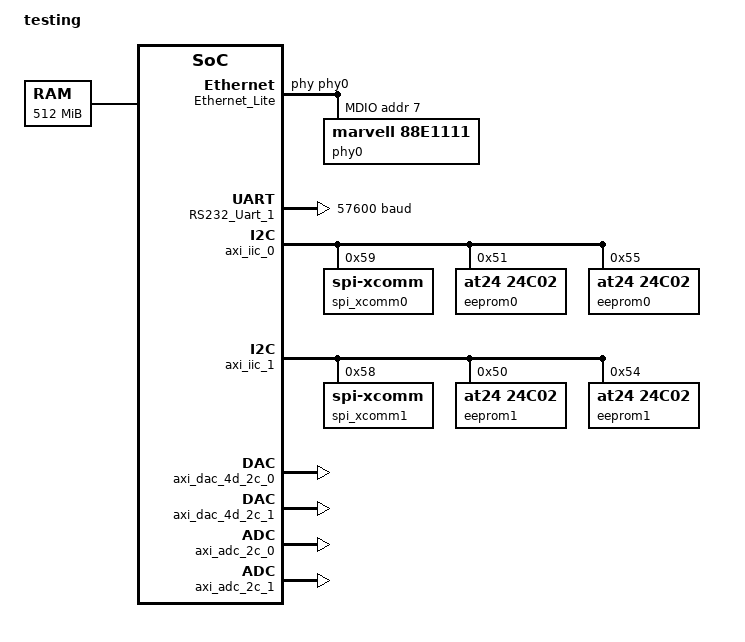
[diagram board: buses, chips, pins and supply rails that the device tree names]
/*
 * Device Tree Generator version: 1.3
 *
 * (C) Copyright 2007-2008 Xilinx, Inc.
 * (C) Copyright 2007-2009 Michal Simek
 *
 * Michal SIMEK <monstr@monstr.eu>
 *
 * This program is free software; you can redistribute it and/or
 * modify it under the terms of the GNU General Public License as
 * published by the Free Software Foundation; either version 2 of
 * the License, or (at your option) any later version.
 *
 * This program is distributed in the hope that it will be useful,
 * but WITHOUT ANY WARRANTY; without even the implied warranty of
 * MERCHANTABILITY or FITNESS FOR A PARTICULAR PURPOSE. See the
 * GNU General Public License for more details.
 *
 * You should have received a copy of the GNU General Public License
 * along with this program; if not, write to the Free Software
 * Foundation, Inc., 59 Temple Place, Suite 330, Boston,
 * MA 02111-1307 USA
 *
 * CAUTION: This file is automatically generated by libgen.
 * Version: Xilinx EDK 14.1 EDK_P.15xf
 *
 * XPS project directory: device-tree_bsp_0
 */

/dts-v1/;
/ {
	#address-cells = <1>;
	#size-cells = <1>;
	compatible = "xlnx,microblaze";
	model = "testing";
	DDR3_SDRAM: memory@c0000000 {
		device_type = "memory";
		reg = < 0xc0000000 0x20000000 >;
	} ;
	aliases {
		ethernet0 = &Ethernet_Lite;
		serial0 = &RS232_Uart_1;
	} ;
	chosen {
		bootargs = "console=ttyS0 root=/dev/ram";
	} ;
	cpus {
		#address-cells = <1>;
		#cpus = <0x1>;
		#size-cells = <0>;
		microblaze_0: cpu@0 {
			clock-frequency = <100000000>;
			compatible = "xlnx,microblaze-8.30.a";
			d-cache-baseaddr = <0xc0000000>;
			d-cache-highaddr = <0xdfffffff>;
			d-cache-line-size = <0x10>;
			d-cache-size = <0x4000>;
			device_type = "cpu";
			i-cache-baseaddr = <0xc0000000>;
			i-cache-highaddr = <0xdfffffff>;
			i-cache-line-size = <0x20>;
			i-cache-size = <0x4000>;
			model = "microblaze,8.30.a";
			reg = <0>;
			timebase-frequency = <100000000>;
			xlnx,addr-tag-bits = <0xf>;
			xlnx,allow-dcache-wr = <0x1>;
			xlnx,allow-icache-wr = <0x1>;
			xlnx,area-optimized = <0x0>;
			xlnx,avoid-primitives = <0x0>;
			xlnx,branch-target-cache-size = <0x0>;
			xlnx,cache-byte-size = <0x4000>;
			xlnx,d-axi = <0x1>;
			xlnx,d-lmb = <0x1>;
			xlnx,d-plb = <0x0>;
			xlnx,data-size = <0x20>;
			xlnx,dcache-addr-tag = <0xf>;
			xlnx,dcache-always-used = <0x1>;
			xlnx,dcache-byte-size = <0x4000>;
			xlnx,dcache-data-width = <0x0>;
			xlnx,dcache-force-tag-lutram = <0x0>;
			xlnx,dcache-interface = <0x0>;
			xlnx,dcache-line-len = <0x4>;
			xlnx,dcache-use-fsl = <0x0>;
			xlnx,dcache-use-writeback = <0x0>;
			xlnx,dcache-victims = <0x0>;
			xlnx,debug-enabled = <0x1>;
			xlnx,div-zero-exception = <0x1>;
			xlnx,dynamic-bus-sizing = <0x1>;
			xlnx,ecc-use-ce-exception = <0x0>;
			xlnx,edge-is-positive = <0x1>;
			xlnx,endianness = <0x1>;
			xlnx,family = "virtex6";
			xlnx,fault-tolerant = <0x0>;
			xlnx,fpu-exception = <0x0>;
			xlnx,freq = <0x5f5e100>;
			xlnx,fsl-data-size = <0x20>;
			xlnx,fsl-exception = <0x0>;
			xlnx,fsl-links = <0x0>;
			xlnx,i-axi = <0x0>;
			xlnx,i-lmb = <0x1>;
			xlnx,i-plb = <0x0>;
			xlnx,icache-always-used = <0x1>;
			xlnx,icache-data-width = <0x0>;
			xlnx,icache-force-tag-lutram = <0x0>;
			xlnx,icache-interface = <0x0>;
			xlnx,icache-line-len = <0x8>;
			xlnx,icache-streams = <0x1>;
			xlnx,icache-use-fsl = <0x0>;
			xlnx,icache-victims = <0x8>;
			xlnx,ill-opcode-exception = <0x1>;
			xlnx,instance = "microblaze_0";
			xlnx,interconnect = <0x2>;
			xlnx,interconnect-m-axi-dc-read-issuing = <0x2>;
			xlnx,interconnect-m-axi-dc-write-issuing = <0x20>;
			xlnx,interconnect-m-axi-dp-read-issuing = <0x1>;
			xlnx,interconnect-m-axi-dp-write-issuing = <0x1>;
			xlnx,interconnect-m-axi-ic-read-issuing = <0x8>;
			xlnx,interconnect-m-axi-ip-read-issuing = <0x1>;
			xlnx,interrupt-is-edge = <0x0>;
			xlnx,lockstep-slave = <0x0>;
			xlnx,mmu-dtlb-size = <0x4>;
			xlnx,mmu-itlb-size = <0x2>;
			xlnx,mmu-privileged-instr = <0x0>;
			xlnx,mmu-tlb-access = <0x3>;
			xlnx,mmu-zones = <0x2>;
			xlnx,number-of-pc-brk = <0x1>;
			xlnx,number-of-rd-addr-brk = <0x0>;
			xlnx,number-of-wr-addr-brk = <0x0>;
			xlnx,opcode-0x0-illegal = <0x1>;
			xlnx,optimization = <0x0>;
			xlnx,pc-width = <0x20>;
			xlnx,pvr = <0x2>;
			xlnx,pvr-user1 = <0x0>;
			xlnx,pvr-user2 = <0x0>;
			xlnx,reset-msr = <0x0>;
			xlnx,sco = <0x0>;
			xlnx,stream-interconnect = <0x0>;
			xlnx,unaligned-exceptions = <0x1>;
			xlnx,use-barrel = <0x1>;
			xlnx,use-branch-target-cache = <0x0>;
			xlnx,use-dcache = <0x1>;
			xlnx,use-div = <0x1>;
			xlnx,use-ext-brk = <0x1>;
			xlnx,use-ext-nm-brk = <0x1>;
			xlnx,use-extended-fsl-instr = <0x0>;
			xlnx,use-fpu = <0x0>;
			xlnx,use-hw-mul = <0x2>;
			xlnx,use-icache = <0x1>;
			xlnx,use-interrupt = <0x1>;
			xlnx,use-mmu = <0x3>;
			xlnx,use-msr-instr = <0x1>;
			xlnx,use-pcmp-instr = <0x1>;
			xlnx,use-reorder-instr = <0x1>;
			xlnx,use-stack-protection = <0x0>;
		} ;
	} ;
	axi4lite_0: axi@0 {
		#address-cells = <1>;
		#size-cells = <1>;
		compatible = "xlnx,axi-interconnect-1.06.a", "simple-bus";
		ranges ;
		Ethernet_Lite: ethernet@40e00000 {
			compatible = "xlnx,axi-ethernetlite-1.01.b", "xlnx,xps-ethernetlite-1.00.a";
			device_type = "network";
			interrupt-parent = <&axi_intc_0>;
			interrupts = < 10 0 >;
			local-mac-address = [ 00 0a 35 ac a4 00 ];
			phy-handle = <&phy0>;
			reg = < 0x40e00000 0x10000 >;
			xlnx,duplex = <0x1>;
			xlnx,family = "virtex6";
			xlnx,include-global-buffers = <0x0>;
			xlnx,include-internal-loopback = <0x0>;
			xlnx,include-mdio = <0x1>;
			xlnx,include-phy-constraints = <0x1>;
			xlnx,instance = "Ethernet_Lite";
			xlnx,interconnect-s-axi-read-acceptance = <0x1>;
			xlnx,interconnect-s-axi-write-acceptance = <0x1>;
			xlnx,rx-ping-pong = <0x0>;
			xlnx,s-axi-aclk-period-ps = <0x2710>;
			xlnx,s-axi-id-width = <0x1>;
			xlnx,s-axi-supports-narrow-burst = <0x0>;
			xlnx,tx-ping-pong = <0x0>;
			mdio {
				#address-cells = <1>;
				#size-cells = <0>;
				phy0: phy@7 {
					compatible = "marvell,88e1111";
					device_type = "ethernet-phy";
					reg = <7>;
				} ;
			} ;
		} ;
		RS232_Uart_1: serial@40600000 {
			clock-frequency = <100000000>;
			compatible = "xlnx,axi-uartlite-1.02.a", "xlnx,xps-uartlite-1.00.a";
			current-speed = <57600>;
			device_type = "serial";
			interrupt-parent = <&axi_intc_0>;
			interrupts = < 11 0 >;
			port-number = <0>;
			reg = < 0x40600000 0x10000 >;
			xlnx,baudrate = <0xe100>;
			xlnx,data-bits = <0x8>;
			xlnx,family = "virtex6";
			xlnx,instance = "RS232_Uart_1";
			xlnx,odd-parity = <0x1>;
			xlnx,s-axi-aclk-freq-hz = <0x5f5e100>;
			xlnx,use-parity = <0x0>;
		} ;

		axi_iic_0: i2c@40820000 {
			compatible = "xlnx,axi-iic-1.02.a", "xlnx,xps-iic-2.00.a";
			interrupt-parent = <&axi_intc_0>;
			interrupts = < 6 2 >;
			reg = < 0x40820000 0x10000 >;
			xlnx,family = "virtex6";
			xlnx,gpo-width = <0x1>;
			xlnx,iic-freq = <0x30d40>;
			xlnx,instance = "axi_iic_0";
			xlnx,s-axi-aclk-freq-hz = <0x5f5e100>;
			xlnx,scl-inertial-delay = <0x5>;
			xlnx,sda-inertial-delay = <0x5>;
			xlnx,sda-level = <0x1>;
			xlnx,ten-bit-adr = <0x0>;
			spi_xcomm0: spi_xcomm0@59 {
				#address-cells = <1>;
				#size-cells = <0>;
				compatible = "spi-xcomm";
				reg = <0x59>;
				clksync0_ad9548: ad9548-lpc@6 {
					#address-cells = <1>;
					#size-cells = <0>;
					compatible = "ad9548";
					reg = <2>;
					spi-3wire;
					spi-max-frequency = <10000000>;
				};
				clk0_ad9523: ad9523-lpc@3 {
					#address-cells = <1>;
					#size-cells = <0>;
					#clock-cells = <1>;
					compatible = "ad9523-1";
					reg = <3>;
					spi-max-frequency = <10000000>;
					spi-3wire;
					clock-output-names = "ad9523-lpc_out0", "ad9523-lpc_out1", "ad9523-lpc_out2", "ad9523-lpc_out3", "ad9523-lpc_out4", "ad9523-lpc_out5", "ad9523-lpc_out6", "ad9523-lpc_out7", "ad9523-lpc_out8", "ad9523-lpc_out9", "ad9523-lpc_out10", "ad9523-lpc_out11", "ad9523-lpc_out12", "ad9523-lpc_out13";
					vcxo-freq = <122880000>;
					refb-diff-rcv-en;
					zd-in-diff-en;
					osc-in-cmos-neg-inp-en;
					refa-r-div = <0>;
					refb-r-div = <0>;
					pll1-feedback-div = <4>;
					pll1-charge-pump-current-nA = <2000>;
					refa-cmos-neg-inp-en;
					pll1-loop-filter-rzero = <3>;
					ref-mode = <3>;
					pll2-charge-pump-current-nA = <420000>;
					pll2-ndiv-a-cnt = <0>;
					pll2-ndiv-b-cnt = <3>;
					pll2-freq-doubler-en;
					pll2-r2-div = <1>;
					pll2-vco-diff-m1 = <3>;
					pll2-vco-diff-m2 = <3>;
					rpole2 = <0>;
					rzero = <2>;
					cpole1 = <2>;
					name = "ad9523-lpc";

					ad9523_0_c0:channel@0 {
						reg = <0>;
						extended-name = "ZD_OUTPUT";
						driver-mode = <2>;
						divider-phase = <0>;
						channel-divider = <8>;
					};
					ad9523_0_c12:channel@12 {
						reg = <12>;
						extended-name = "DAC_CLK";
						driver-mode = <1>;
						divider-phase = <0>;
						channel-divider = <2>;
					};
					ad9523_0_c2:channel@2 {
						reg = <2>;
						extended-name = "ADC_CLK";
						driver-mode = <3>;
						divider-phase = <0>;
						channel-divider = <4>;
					};
					ad9523_0_c10:channel@10 {
						reg = <10>;
						extended-name = "DAC_REF_CLK";
						driver-mode = <2>;
						divider-phase = <0>;
						channel-divider = <16>;
					};
					ad9523_0_c5:channel@5 {
						reg = <5>;
						extended-name = "TX_LO_REF_CLK";
						driver-mode = <8>; /* HiZ on - */
						divider-phase = <0>;
						channel-divider = <8>;
					};
					ad9523_0_c6:channel@6 {
						reg = <6>;
						extended-name = "DAC_DCO_CLK";
						driver-mode = <3>;
						divider-phase = <0>;
						channel-divider = <2>;
					};
					ad9523_0_c7:channel@7 {
						reg = <7>;
						extended-name = "ADC_SYNC_CLK";
						driver-mode = <8>; /* HiZ on - */
						divider-phase = <1>;
						channel-divider = <32>;
					};
					ad9523_0_c9:channel@9 {
						reg = <9>;
						extended-name = "RX_LO_REF_CLK";
						driver-mode = <8>; /* HiZ on - */
						divider-phase = <0>;
						channel-divider = <8>;
					};
				};
				adc0_ad9467: ad9467@1 {
					#address-cells = <1>;
					#size-cells = <0>;
					compatible = "ad9643";
					reg = <1>;
					spi-max-frequency = <10000000>;
					clocks = <&clk0_ad9523 2>;
					clock-names = "clkin";
				};
				dac0_ad9122: ad9122@0 {
					#address-cells = <1>;
					#size-cells = <0>;
					compatible = "ad9122";
					reg = <0>;
					spi-max-frequency = <10000000>;
					clocks = <&clk0_ad9523 6>, <&clk0_ad9523 12>, <&clk0_ad9523 10>;
					clock-names = "data_clk", "dac_clk", "ref_clk";
					dac-fcenter-shift = <0>;
					dac-interp-factor = <1>;
					dac-data-rate = <491520000>;
				};

				vga0_ad8366: ad8366-lpc@6 {
					#address-cells = <1>;
					#size-cells = <0>;
					compatible = "ad8366";
					reg = <6>;
					spi-3wire;
					spi-max-frequency = <10000000>;
				};

				lo_pll0_rx_adf4351: adf4351-rx-lpc@4 {
					#address-cells = <1>;
					#size-cells = <0>;
					compatible = "adf4351";
					reg = <4>;
					spi-max-frequency = <10000000>;
					clocks = <&clk0_ad9523 9>;
					clock-names = "clkin";
					adf4350-channel-spacing = <10000>;
					adf4350-power-up-frequency = <2400000000>;
					adf4350-reg2-pd-polarity-pos-en;
					adf4350-reg2-charge-pump-curr-ua = <2500>;
					adf4350-reg4-output-pwr = <3>;
					adf4350-reg4-mute-till-lock-en;
				};

				lo_pll0_tx_adf4351: adf4351-tx-lpc@5 {
					#address-cells = <1>;
					#size-cells = <0>;
					compatible = "adf4351";
					reg = <5>;
					spi-max-frequency = <10000000>;
					clocks = <&clk0_ad9523 5>;
					clock-names = "clkin";
					adf4350-channel-spacing = <10000>;
					adf4350-power-up-frequency = <2400000000>;
					adf4350-reg2-pd-polarity-pos-en;
					adf4350-reg2-charge-pump-curr-ua = <2500>;
					adf4350-reg4-output-pwr = <3>;
					adf4350-reg4-mute-till-lock-en;
				};

			};
			eeprom0@51 {
				#address-cells = <1>;
				#size-cells = <0>;
				compatible = "at24,24c02";
				reg = <0x51>;
			};
			eeprom0@55 {
				#address-cells = <1>;
				#size-cells = <0>;
				compatible = "at24,24c02";
				reg = <0x55>;
			};
		} ;
		axi_iic_1: i2c@40800000 {
			compatible = "xlnx,axi-iic-1.02.a", "xlnx,xps-iic-2.00.a";
			interrupt-parent = <&axi_intc_0>;
			interrupts = < 5 2 >;
			reg = < 0x40800000 0x10000 >;
			xlnx,family = "virtex6";
			xlnx,gpo-width = <0x1>;
			xlnx,iic-freq = <0x61a80>;
			xlnx,instance = "axi_iic_1";
			xlnx,s-axi-aclk-freq-hz = <0x5f5e100>;
			xlnx,scl-inertial-delay = <0x5>;
			xlnx,sda-inertial-delay = <0x5>;
			xlnx,sda-level = <0x1>;
			xlnx,ten-bit-adr = <0x0>;
			spi_xcomm1: spi_xcomm1@58 {
				#address-cells = <1>;
				#size-cells = <0>;
				compatible = "spi-xcomm";
				reg = <0x58>;
				clksync1_ad9548: ad9548-hpc@6 {
					#address-cells = <1>;
					#size-cells = <0>;
					compatible = "ad9548";
					reg = <2>;
					spi-3wire;
					spi-max-frequency = <10000000>;
				};
				clk1_ad9523: ad9523-hpc@3 {
					#address-cells = <1>;
					#size-cells = <0>;
					#clock-cells = <1>;
					compatible = "ad9523-1";
					reg = <3>;
					spi-max-frequency = <10000000>;
					spi-3wire;
					clock-output-names = "ad9523-hpc_out0", "ad9523-hpc_out1", "ad9523-hpc_out2", "ad9523-hpc_out3", "ad9523-hpc_out4", "ad9523-hpc_out5", "ad9523-hpc_out6", "ad9523-hpc_out7", "ad9523-hpc_out8", "ad9523-hpc_out9", "ad9523-hpc_out10", "ad9523-hpc_out11", "ad9523-hpc_out12", "ad9523-hpc_out13";
					vcxo-freq = <122880000>;
					refb-diff-rcv-en;
					zd-in-diff-en;
					osc-in-cmos-neg-inp-en;
					refa-r-div = <0>;
					refb-r-div = <0>;
					pll1-feedback-div = <4>;
					pll1-charge-pump-current-nA = <2000>;
					refa-cmos-neg-inp-en;
					pll1-loop-filter-rzero = <3>;
					ref-mode = <3>;
					pll2-charge-pump-current-nA = <420000>;
					pll2-ndiv-a-cnt = <0>;
					pll2-ndiv-b-cnt = <3>;
					pll2-freq-doubler-en;
					pll2-r2-div = <1>;
					pll2-vco-diff-m1 = <3>;
					pll2-vco-diff-m2 = <3>;
					rpole2 = <0>;
					rzero = <2>;
					cpole1 = <2>;
					name = "ad9523-hpc";

					ad9523_1_c0:channel@0 {
						reg = <0>;
						extended-name = "ZD_OUTPUT";
						driver-mode = <2>;
						divider-phase = <0>;
						channel-divider = <8>;
					};
					ad9523_1_c12:channel@12 {
						reg = <12>;
						extended-name = "DAC_CLK";
						driver-mode = <1>;
						divider-phase = <0>;
						channel-divider = <2>;
					};
					ad9523_1_c2:channel@2 {
						reg = <2>;
						extended-name = "ADC_CLK";
						driver-mode = <3>;
						divider-phase = <0>;
						channel-divider = <4>;
					};
					ad9523_1_c10:channel@10 {
						reg = <10>;
						extended-name = "DAC_REF_CLK";
						driver-mode = <2>;
						divider-phase = <0>;
						channel-divider = <16>;
					};
					ad9523_1_c5:channel@5 {
						reg = <5>;
						extended-name = "TX_LO_REF_CLK";
						driver-mode = <8>; /* HiZ on - */
						divider-phase = <0>;
						channel-divider = <8>;
					};
					ad9523_1_c6:channel@6 {
						reg = <6>;
						extended-name = "DAC_DCO_CLK";
						driver-mode = <3>;
						divider-phase = <0>;
						channel-divider = <2>;
					};
					ad9523_1_c7:channel@7 {
						reg = <7>;
						extended-name = "ADC_SYNC_CLK";
						driver-mode = <8>; /* HiZ on - */
						divider-phase = <1>;
						channel-divider = <32>;
					};
					ad9523_1_c9:channel@9 {
						reg = <9>;
						extended-name = "RX_LO_REF_CLK";
						driver-mode = <8>; /* HiZ on - */
						divider-phase = <0>;
						channel-divider = <8>;
					};
				};
				adc1_ad9467: ad9467@1 {
					#address-cells = <1>;
					#size-cells = <0>;
					compatible = "ad9643";
					reg = <1>;
					spi-max-frequency = <10000000>;
					clocks = <&clk1_ad9523 2>;
					clock-names = "clkin";
				};
				dac1_ad9122: ad9122@0 {
					#address-cells = <1>;
					#size-cells = <0>;
					compatible = "ad9122";
					reg = <0>;
					spi-max-frequency = <10000000>;
					clocks = <&clk1_ad9523 6>, <&clk1_ad9523 12>, <&clk1_ad9523 10>;
					clock-names = "data_clk", "dac_clk", "ref_clk";
					dac-fcenter-shift = <0>;
					dac-interp-factor = <1>;
					dac-data-rate = <491520000>;
				};
				vga1_ad8366: ad8366-hpc@6 {
					#address-cells = <1>;
					#size-cells = <0>;
					compatible = "ad8366";
					reg = <6>;
					spi-3wire;
					spi-max-frequency = <10000000>;
				};

				lo_pll1_rx_adf4351: adf4351-rx-hpc@4 {
					#address-cells = <1>;
					#size-cells = <0>;
					compatible = "adf4351";
					reg = <4>;
					spi-max-frequency = <10000000>;
					clocks = <&clk1_ad9523 9>;
					clock-names = "clkin";
					adf4350-channel-spacing = <10000>;
					adf4350-power-up-frequency = <2400000000>;
					adf4350-reg2-pd-polarity-pos-en;
					adf4350-reg2-charge-pump-curr-ua = <2500>;
					adf4350-reg4-output-pwr = <3>;
					adf4350-reg4-mute-till-lock-en;
				};

				lo_pll1_tx_adf4351: adf4351-tx-hpc@5 {
					#address-cells = <1>;
					#size-cells = <0>;
					compatible = "adf4351";
					reg = <5>;
					spi-max-frequency = <10000000>;
					clocks = <&clk1_ad9523 5>;
					clock-names = "clkin";
					adf4350-channel-spacing = <10000>;
					adf4350-power-up-frequency = <2400000000>;
					adf4350-reg2-pd-polarity-pos-en;
					adf4350-reg2-charge-pump-curr-ua = <2500>;
					adf4350-reg4-output-pwr = <3>;
					adf4350-reg4-mute-till-lock-en;
				};

			};
			eeprom1@50 {
				#address-cells = <1>;
				#size-cells = <0>;
				compatible = "at24,24c02";
				reg = <0x50>;
			};
			eeprom1@54 {
				#address-cells = <1>;
				#size-cells = <0>;
				compatible = "at24,24c02";
				reg = <0x54>;
			};
		} ;

		axi_gpio_0: gpio@40000000 {
			compatible = "xlnx,axi-xlnx-lcd-1.00.a";
			reg = < 0x40000000 0x10000 >;
			xlnx,all-inputs = <0x0>;
			xlnx,all-inputs-2 = <0x0>;
			xlnx,dout-default = <0x0>;
			xlnx,dout-default-2 = <0x0>;
			xlnx,family = "virtex6";
			xlnx,gpio-width = <0x7>;
			xlnx,gpio2-width = <0x20>;
			xlnx,instance = "axi_gpio_0";
			xlnx,interrupt-present = <0x1>;
			xlnx,is-dual = <0x0>;
			xlnx,tri-default = <0xffffffff>;
			xlnx,tri-default-2 = <0xffffffff>;
		} ;

		axi_gpio_1: gpio@40040000 {
			compatible = "xlnx,axi-gpio-1.01.b", "xlnx,xps-gpio-1.00.a";
			interrupt-parent = <&axi_intc_0>;
			interrupts = < 0 2 >;
			reg = < 0x40040000 0x10000 >;
			xlnx,all-inputs = <0x0>;
			xlnx,all-inputs-2 = <0x0>;
			xlnx,dout-default = <0x0>;
			xlnx,dout-default-2 = <0x0>;
			xlnx,family = "virtex6";
			xlnx,gpio-width = <0xd>;
			xlnx,gpio2-width = <0xd>;
			xlnx,instance = "axi_gpio_1";
			xlnx,interrupt-present = <0x1>;
			xlnx,is-dual = <0x1>;
			xlnx,tri-default = <0xffffffff>;
			xlnx,tri-default-2 = <0xffffffff>;
		} ;

		axi_dac_4d_2c_0: cf-ad9122-core-lpc@7a020000 {
			compatible = "xlnx,axi-dac-4d-2c-1.00.a";
			reg = < 0x7a020000 0x10000 >;
			spibus-connected = <&dac0_ad9122>;
			dac-sample-frequency = <491520000>;
			dma-request = <&axi_vdma_0 0>;
			xlnx,dphase-timeout = <0x8>;
			xlnx,family = "virtex6";
			xlnx,num-mem = <0x1>;
			xlnx,num-reg = <0x1>;
			xlnx,s-axi-min-size = <0x1ff>;
			xlnx,slv-awidth = <0x20>;
			xlnx,slv-dwidth = <0x20>;
			xlnx,use-wstrb = <0x0>;
		} ;
		axi_dac_4d_2c_1: cf-ad9122-core-hpc@7a000000 {
			compatible = "xlnx,axi-dac-4d-2c-1.00.a";
			reg = < 0x7a000000 0x10000 >;
			dac-sample-frequency = <491520000>;
			spibus-connected = <&dac1_ad9122>;
			dma-request = <&axi_vdma_1 0>;
			xlnx,dphase-timeout = <0x8>;
			xlnx,family = "virtex6";
			xlnx,num-mem = <0x1>;
			xlnx,num-reg = <0x1>;
			xlnx,s-axi-min-size = <0x1ff>;
			xlnx,slv-awidth = <0x20>;
			xlnx,slv-dwidth = <0x20>;
			xlnx,use-wstrb = <0x0>;
		} ;

		axi_adc_2c_0: cf-ad9643-core-lpc@7c820000 {
			compatible = "xlnx,axi-adc-2c-1.00.a";
			reg = < 0x7c820000 0x10000 >;
			dma-request = <&axi_dma_0 0>;
			spibus-connected = <&adc0_ad9467>;
//			spibus-slaveselect-connected = <0x1>;
			dco-output-delay = <0x8c>;
			xlnx,cf-buftype = <0x1>;
			xlnx,dphase-timeout = <0x8>;
			xlnx,family = "virtex6";
			xlnx,num-mem = <0x1>;
			xlnx,num-reg = <0x1>;
			xlnx,s-axi-min-size = <0x1ff>;
			xlnx,slv-awidth = <0x20>;
			xlnx,slv-dwidth = <0x20>;
			xlnx,use-wstrb = <0x0>;
		} ;
		axi_adc_2c_1: cf-ad9643-core-hpc@7c800000 {
			compatible = "xlnx,axi-adc-2c-1.00.a";
			reg = < 0x7c800000 0x10000 >;
			dma-request = <&axi_dma_1 0>;
			spibus-connected = <&adc1_ad9467>;
//			spibus-slaveselect-connected = <0x1>;
			dco-output-delay = <0x89>;
			xlnx,cf-buftype = <0x1>;
			xlnx,dphase-timeout = <0x8>;
			xlnx,family = "virtex6";
			xlnx,num-mem = <0x1>;
			xlnx,num-reg = <0x1>;
			xlnx,s-axi-min-size = <0x1ff>;
			xlnx,slv-awidth = <0x20>;
			xlnx,slv-dwidth = <0x20>;
			xlnx,use-wstrb = <0x0>;
		} ;
		axi_dma_0: axidma@41e40000 {
			#address-cells = <1>;
			#size-cells = <1>;
			#dma-cells = <1>;
			compatible = "xlnx,axi-dma";
			ranges = < 0x41e40000 0x41e40000 0x10000 >;
			reg = < 0x41e40000 0x10000 >;
			xlnx,sg-include-stscntrl-strm = <0x0>;
			dma-channel@41e40030 {
				compatible = "xlnx,axi-dma-s2mm-channel";
				interrupt-parent = <&axi_intc_0>;
				interrupts = < 8 2 >;
				xlnx,datawidth = <0x40>;
				xlnx,include-dre = <0x0>;
			} ;
		} ;
		axi_dma_1: axidma@41e20000 {
			#address-cells = <1>;
			#size-cells = <1>;
			#dma-cells = <1>;
			compatible = "xlnx,axi-dma";
			ranges = < 0x41e20000 0x41e20000 0x10000 >;
			reg = < 0x41e20000 0x10000 >;
			xlnx,sg-include-stscntrl-strm = <0x0>;
			dma-channel@41e20030 {
				compatible = "xlnx,axi-dma-s2mm-channel";
				interrupt-parent = <&axi_intc_0>;
				interrupts = < 7 2 >;
				xlnx,datawidth = <0x40>;
				xlnx,include-dre = <0x0>;
			} ;
		} ;
		axi_intc_0: interrupt-controller@41200000 {
			#interrupt-cells = <0x2>;
			compatible = "xlnx,axi-intc-1.02.a", "xlnx,xps-intc-1.00.a";
			interrupt-controller ;
			reg = < 0x41200000 0x10000 >;
			xlnx,kind-of-intr = <0xc00>;
			xlnx,num-intr-inputs = <0xc>;
		} ;

		axi_dma_2: axidma@41e00000 {
			#address-cells = <1>;
			#size-cells = <1>;
			#dma-cells = <1>;
			compatible = "xlnx,axi-dma";
			ranges = < 0x41e00000 0x41e00000 0x10000 >;
			reg = < 0x41e00000 0x10000 >;
//			xlnx,sg-include-stscntrl-strm = <0x0>;
			dma-channel@41e00000 {
				compatible = "xlnx,axi-dma-mm2s-channel";
				interrupt-parent = <&axi_intc_0>;
				interrupts = < 2 2 >;
				xlnx,datawidth = <0x20>;
				xlnx,include-dre = <0x0>;
			} ;
			dma-channel@41e00030 {
				compatible = "xlnx,axi-dma-s2mm-channel";
				interrupt-parent = <&axi_intc_0>;
				interrupts = < 1 2 >;
				xlnx,datawidth = <0x20>;
				xlnx,include-dre = <0x0>;
			} ;
		} ;
		axi_fft_0: axi-fft@7ee00000 {
			compatible = "xlnx,axi-fft-1.00.a";
			reg = < 0x7ee00000 0x10000 >;
			dma-request = <&axi_dma_2 0
					&axi_dma_2 1>;
			xlnx,dphase-timeout = <0x8>;
			xlnx,family = "virtex6";
			xlnx,num-mem = <0x1>;
			xlnx,num-reg = <0x1>;
			xlnx,s-axi-min-size = <0x1ff>;
			xlnx,slv-awidth = <0x20>;
			xlnx,slv-dwidth = <0x20>;
			xlnx,use-wstrb = <0x0>;
		} ;
		axi_timer_0: timer@41c00000 {
			clock-frequency = <100000000>;
			compatible = "xlnx,axi-timer-1.03.a", "xlnx,xps-timer-1.00.a";
			interrupt-parent = <&axi_intc_0>;
			interrupts = < 9 2 >;
			reg = < 0x41c00000 0x10000 >;
			xlnx,count-width = <0x20>;
			xlnx,family = "virtex6";
			xlnx,gen0-assert = <0x1>;
			xlnx,gen1-assert = <0x1>;
			xlnx,instance = "axi_timer_0";
			xlnx,one-timer-only = <0x0>;
			xlnx,trig0-assert = <0x1>;
			xlnx,trig1-assert = <0x1>;
		} ;
		axi_vdma_0: axivdma@7e220000 {
			#address-cells = <1>;
			#size-cells = <1>;
			#dma-cells = <1>;
			compatible = "xlnx,axi-vdma";
			ranges = < 0x7e220000 0x7e220000 0x10000 >;
			reg = < 0x7e220000 0x10000 >;
//			xlnx,include-sg = <0x0>;
			xlnx,num-fstores = <0x3>;
			dma-channel@7e220000 {
				compatible = "xlnx,axi-vdma-mm2s-channel";
				interrupt-parent = <&axi_intc_0>;
				interrupts = < 4 2 >;
				xlnx,datawidth = <0x40>;
				xlnx,genlock-mode = <0x0>;
				xlnx,include-dre = <0x0>;
			} ;
		} ;
		axi_vdma_1: axivdma@7e200000 {
			#address-cells = <1>;
			#size-cells = <1>;
			#dma-cells = <1>;
			compatible = "xlnx,axi-vdma";
			ranges = < 0x7e200000 0x7e200000 0x10000 >;
			reg = < 0x7e200000 0x10000 >;
//			xlnx,include-sg = <0x0>;
			xlnx,num-fstores = <0x3>;
			dma-channel@7e200000 {
				compatible = "xlnx,axi-vdma-mm2s-channel";
				interrupt-parent = <&axi_intc_0>;
				interrupts = < 3 2 >;
				xlnx,datawidth = <0x40>;
				xlnx,genlock-mode = <0x0>;
				xlnx,include-dre = <0x0>;
			} ;
		} ;
		debug_module: debug@41400000 {
			compatible = "xlnx,mdm-2.00.b";
			reg = < 0x41400000 0x10000 >;
			xlnx,family = "virtex6";
			xlnx,interconnect = <0x2>;
			xlnx,jtag-chain = <0x2>;
			xlnx,mb-dbg-ports = <0x1>;
			xlnx,use-uart = <0x1>;
		} ;
	} ;
} ;
